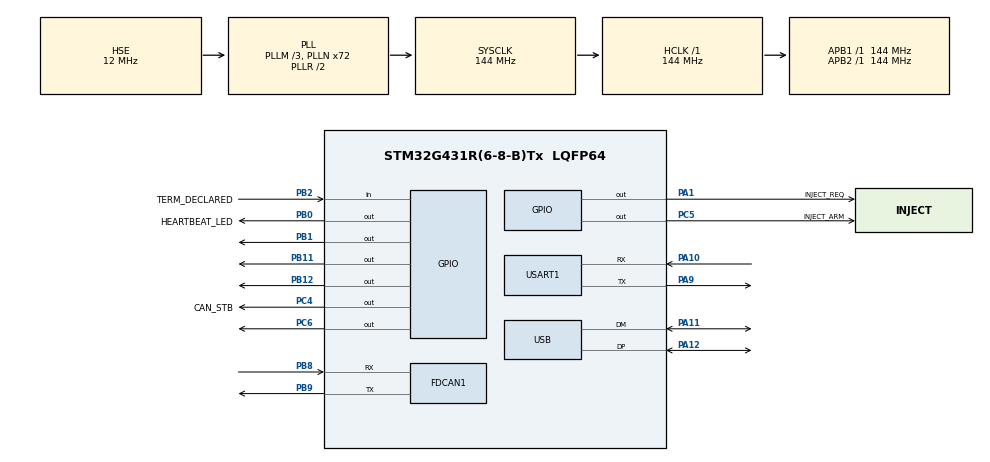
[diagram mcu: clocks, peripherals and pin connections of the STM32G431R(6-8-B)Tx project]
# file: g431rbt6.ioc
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FDCAN1.CalculateBaudRateNominal=8000000
FDCAN1.CalculateTimeBitNominal=125
FDCAN1.CalculateTimeQuantumNominal=41.666666666666664
FDCAN1.DataPrescaler=6
FDCAN1.DataSyncJumpWidth=2
FDCAN1.DataTimeSeg1=13
FDCAN1.DataTimeSeg2=2
FDCAN1.ExtFiltersNbr=1
FDCAN1.FrameFormat=FDCAN_FRAME_FD_NO_BRS
FDCAN1.NominalPrescaler=2
FDCAN1.NominalSyncJumpWidth=1
FDCAN1.ProtocolException=ENABLE
FDCAN1.StdFiltersNbr=1
Mcu.Family=STM32G4
Mcu.Name=STM32G431R(6-8-B)Tx
Mcu.Package=LQFP64
NVIC.FDCAN1_IT0_IRQn=true\:5\:0\:true\:false\:true\:true\:true\:true
NVIC.PriorityGroup=NVIC_PRIORITYGROUP_4
NVIC.TIM6_DAC_IRQn=true\:4\:0\:true\:false\:true\:false\:true\:true
NVIC.TimeBase=TIM6_DAC_IRQn
NVIC.TimeBaseIP=TIM6
NVIC.USB_LP_IRQn=true\:6\:0\:true\:false\:true\:true\:true\:true
PA1.GPIO_Label=INJECT_REQ
PA1.Signal=GPIO_Output
PA10.Mode=Asynchronous
PA10.Signal=USART1_RX
PA11.Mode=Device
PA11.Signal=USB_DM
PA12.Mode=Device
PA12.Signal=USB_DP
PA13.Mode=Serial_Wire
PA13.Signal=SYS_JTMS-SWDIO
PA14.Mode=Serial_Wire
PA14.Signal=SYS_JTCK-SWCLK
PA9.Mode=Asynchronous
PA9.Signal=USART1_TX
PB0.GPIO_Label=HEARTBEAT_LED
PB0.PinState=GPIO_PIN_SET
PB0.Signal=GPIO_Output
PB1.PinState=GPIO_PIN_SET
PB1.Signal=GPIO_Output
PB11.PinState=GPIO_PIN_SET
PB11.Signal=GPIO_Output
PB12.PinState=GPIO_PIN_SET
PB12.Signal=GPIO_Output
PB2.GPIO_Label=TERM_DECLARED
PB2.Signal=GPIO_Input
PB8-BOOT0.Mode=FDCAN_Activate
PB8-BOOT0.Signal=FDCAN1_RX
PB9.Mode=FDCAN_Activate
PB9.Signal=FDCAN1_TX
PC4.GPIO_Label=CAN_STB
PC4.PinState=GPIO_PIN_SET
PC4.Signal=GPIO_Output
PC5.GPIO_Label=INJECT_ARM
PC5.Signal=GPIO_Output
PC6.Signal=GPIO_Output
PF0-OSC_IN.Mode=HSE-External-Oscillator
PF0-OSC_IN.Signal=RCC_OSC_IN
PF1-OSC_OUT.Mode=HSE-External-Oscillator
PF1-OSC_OUT.Signal=RCC_OSC_OUT
ProjectManager.HeapSize=0x200
ProjectManager.StackSize=0x400
ProjectManager.TargetToolchain=CMake
RCC.ADC12Freq_Value=144000000
RCC.AHBFreq_Value=144000000
RCC.APB1Freq_Value=144000000
RCC.APB1TimFreq_Value=144000000
RCC.APB2Freq_Value=144000000
RCC.APB2TimFreq_Value=144000000
RCC.CortexFreq_Value=144000000
RCC.EXTERNAL_CLOCK_VALUE=12288000
RCC.EnbaleCSS=true
RCC.FDCANCLockSelection=RCC_FDCANCLKSOURCE_PLL
RCC.HCLKFreq_Value=144000000
RCC.HSE_VALUE=12000000
RCC.HSI48_VALUE=48000000
RCC.HSI_VALUE=16000000
RCC.LSE_VALUE=32768
RCC.PLLM=RCC_PLLM_DIV3
RCC.PLLN=72
RCC.PLLQ=RCC_PLLQ_DIV6
RCC.PLLSourceVirtual=RCC_PLLSOURCE_HSE
RCC.SYSCLKFreq_VALUE=144000000
RCC.SYSCLKSource=RCC_SYSCLKSOURCE_PLLCLK
RCC.USBFreq_Value=48000000
RCC.VCOOutputFreq_Value=288000000
USART1.VirtualMode-Asynchronous=VM_ASYNC
VP_SYS_VS_DBSignals.Mode=DisableDeadBatterySignals
VP_SYS_VS_tim6.Mode=TIM6
board=custom

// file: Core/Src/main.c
/* USER CODE BEGIN Header */
/**
  ******************************************************************************
  * @file           : main.c
  * @brief          : Main program body
  ******************************************************************************
  * @attention
  *
  * Copyright (c) 2026 STMicroelectronics.
  * All rights reserved.
  *
  * This software is licensed under terms that can be found in the LICENSE file
  * in the root directory of this software component.
  * If no LICENSE file comes with this software, it is provided AS-IS.
  *
  ******************************************************************************
  */
/* USER CODE END Header */
#include "main.h"

/* USER CODE BEGIN Includes */
#include "xcan_board.h"
/* USER CODE END Includes */

FDCAN_HandleTypeDef hfdcan1;

UART_HandleTypeDef huart1;

PCD_HandleTypeDef hpcd_USB_FS;

void SystemClock_Config(void);
static void MX_GPIO_Init(void);
static void MX_USART1_UART_Init(void);
static void MX_USB_PCD_Init(void);
static void MX_FDCAN1_Init(void);

int main(void)
{

  /* USER CODE BEGIN 1 */
  xcan_board_safe();
  /* USER CODE END 1 */

  /* MCU Configuration--------------------------------------------------------*/

  /* Reset of all peripherals, Initializes the Flash interface and the Systick. */
  HAL_Init();

  /* Configure the system clock */
  SystemClock_Config();

  /* Initialize all configured peripherals */
  MX_GPIO_Init();
  MX_USART1_UART_Init();
  MX_USB_PCD_Init();
  MX_FDCAN1_Init();
  /* USER CODE BEGIN 2 */
  xcan_board_init();
  xcan_start();
  /* USER CODE END 2 */

  /* Infinite loop */
  while (1)
  {

  }
}

void SystemClock_Config(void)
{
  RCC_OscInitTypeDef RCC_OscInitStruct = {0};
  RCC_ClkInitTypeDef RCC_ClkInitStruct = {0};

  /** Configure the main internal regulator output voltage
  */
  HAL_PWREx_ControlVoltageScaling(PWR_REGULATOR_VOLTAGE_SCALE1);

  /** Initializes the RCC Oscillators according to the specified parameters
  * in the RCC_OscInitTypeDef structure.
  */
  RCC_OscInitStruct.OscillatorType = RCC_OSCILLATORTYPE_HSE;
  RCC_OscInitStruct.HSEState = RCC_HSE_ON;
  RCC_OscInitStruct.PLL.PLLState = RCC_PLL_ON;
  RCC_OscInitStruct.PLL.PLLSource = RCC_PLLSOURCE_HSE;
  RCC_OscInitStruct.PLL.PLLM = RCC_PLLM_DIV3;
  RCC_OscInitStruct.PLL.PLLN = 72;
  RCC_OscInitStruct.PLL.PLLP = RCC_PLLP_DIV2;
  RCC_OscInitStruct.PLL.PLLQ = RCC_PLLQ_DIV6;
  RCC_OscInitStruct.PLL.PLLR = RCC_PLLR_DIV2;
  if (HAL_RCC_OscConfig(&RCC_OscInitStruct) != HAL_OK)
  {
    Error_Handler();
  }

  /** Initializes the CPU, AHB and APB buses clocks
  */
  RCC_ClkInitStruct.ClockType = RCC_CLOCKTYPE_HCLK|RCC_CLOCKTYPE_SYSCLK
                              |RCC_CLOCKTYPE_PCLK1|RCC_CLOCKTYPE_PCLK2;
  RCC_ClkInitStruct.SYSCLKSource = RCC_SYSCLKSOURCE_PLLCLK;
  RCC_ClkInitStruct.AHBCLKDivider = RCC_SYSCLK_DIV1;
  RCC_ClkInitStruct.APB1CLKDivider = RCC_HCLK_DIV1;
  RCC_ClkInitStruct.APB2CLKDivider = RCC_HCLK_DIV1;

  if (HAL_RCC_ClockConfig(&RCC_ClkInitStruct, FLASH_LATENCY_4) != HAL_OK)
  {
    Error_Handler();
  }

  /** Enables the Clock Security System
  */
  HAL_RCC_EnableCSS();
}

static void MX_FDCAN1_Init(void)
{

  hfdcan1.Instance = FDCAN1;
  hfdcan1.Init.ClockDivider = FDCAN_CLOCK_DIV1;
  hfdcan1.Init.FrameFormat = FDCAN_FRAME_FD_NO_BRS;
  hfdcan1.Init.Mode = FDCAN_MODE_NORMAL;
  hfdcan1.Init.AutoRetransmission = DISABLE;
  hfdcan1.Init.TransmitPause = DISABLE;
  hfdcan1.Init.ProtocolException = ENABLE;
  hfdcan1.Init.NominalPrescaler = 2;
  hfdcan1.Init.NominalSyncJumpWidth = 1;
  hfdcan1.Init.NominalTimeSeg1 = 1;
  hfdcan1.Init.NominalTimeSeg2 = 1;
  hfdcan1.Init.DataPrescaler = 6;
  hfdcan1.Init.DataSyncJumpWidth = 2;
  hfdcan1.Init.DataTimeSeg1 = 13;
  hfdcan1.Init.DataTimeSeg2 = 2;
  hfdcan1.Init.StdFiltersNbr = 1;
  hfdcan1.Init.ExtFiltersNbr = 1;
  hfdcan1.Init.TxFifoQueueMode = FDCAN_TX_FIFO_OPERATION;
  if (HAL_FDCAN_Init(&hfdcan1) != HAL_OK)
  {
    Error_Handler();
  }

}

static void MX_USART1_UART_Init(void)
{

  huart1.Instance = USART1;
  huart1.Init.BaudRate = 115200;
  huart1.Init.WordLength = UART_WORDLENGTH_8B;
  huart1.Init.StopBits = UART_STOPBITS_1;
  huart1.Init.Parity = UART_PARITY_NONE;
  huart1.Init.Mode = UART_MODE_TX_RX;
  huart1.Init.HwFlowCtl = UART_HWCONTROL_NONE;
  huart1.Init.OverSampling = UART_OVERSAMPLING_16;
  huart1.Init.OneBitSampling = UART_ONE_BIT_SAMPLE_DISABLE;
  huart1.Init.ClockPrescaler = UART_PRESCALER_DIV1;
  huart1.AdvancedInit.AdvFeatureInit = UART_ADVFEATURE_NO_INIT;
  if (HAL_UART_Init(&huart1) != HAL_OK)
  {
    Error_Handler();
  }
  if (HAL_UARTEx_SetTxFifoThreshold(&huart1, UART_TXFIFO_THRESHOLD_1_8) != HAL_OK)
  {
    Error_Handler();
  }
  if (HAL_UARTEx_SetRxFifoThreshold(&huart1, UART_RXFIFO_THRESHOLD_1_8) != HAL_OK)
  {
    Error_Handler();
  }
  if (HAL_UARTEx_DisableFifoMode(&huart1) != HAL_OK)
  {
    Error_Handler();
  }

}

static void MX_USB_PCD_Init(void)
{

  /* USER CODE BEGIN USB_Init 0 */
  /* CherryUSB owns the controller; CubeMX retains clock/pin configuration. */
  hpcd_USB_FS.Instance = USB;
  HAL_PCD_MspInit(&hpcd_USB_FS);
  return;
  /* USER CODE END USB_Init 0 */

  hpcd_USB_FS.Instance = USB;
  hpcd_USB_FS.Init.dev_endpoints = 8;
  hpcd_USB_FS.Init.speed = PCD_SPEED_FULL;
  hpcd_USB_FS.Init.phy_itface = PCD_PHY_EMBEDDED;
  hpcd_USB_FS.Init.Sof_enable = DISABLE;
  hpcd_USB_FS.Init.low_power_enable = DISABLE;
  hpcd_USB_FS.Init.lpm_enable = DISABLE;
  hpcd_USB_FS.Init.battery_charging_enable = DISABLE;
  if (HAL_PCD_Init(&hpcd_USB_FS) != HAL_OK)
  {
    Error_Handler();
  }

}

static void MX_GPIO_Init(void)
{
  GPIO_InitTypeDef GPIO_InitStruct = {0};

  /* GPIO Ports Clock Enable */
  __HAL_RCC_GPIOC_CLK_ENABLE();
  __HAL_RCC_GPIOF_CLK_ENABLE();
  __HAL_RCC_GPIOG_CLK_ENABLE();
  __HAL_RCC_GPIOA_CLK_ENABLE();
  __HAL_RCC_GPIOB_CLK_ENABLE();
  __HAL_RCC_GPIOD_CLK_ENABLE();

  /*Configure GPIO pin Output Level */
  HAL_GPIO_WritePin(INJECT_REQ_GPIO_Port, INJECT_REQ_Pin, GPIO_PIN_RESET);

  /*Configure GPIO pin Output Level */
  HAL_GPIO_WritePin(CAN_STB_GPIO_Port, CAN_STB_Pin, GPIO_PIN_SET);

  /*Configure GPIO pin Output Level */
  HAL_GPIO_WritePin(GPIOC, INJECT_ARM_Pin|GPIO_PIN_6, GPIO_PIN_RESET);

  /*Configure GPIO pin Output Level */
  HAL_GPIO_WritePin(GPIOB, HEARTBEAT_LED_Pin|GPIO_PIN_1|GPIO_PIN_11|GPIO_PIN_12, GPIO_PIN_SET);

  /*Configure GPIO pins : PC13 PC14 PC15 PC0
                           PC1 PC2 PC3 PC7
                           PC8 PC9 PC10 PC11
                           PC12 */
  GPIO_InitStruct.Pin = GPIO_PIN_13|GPIO_PIN_14|GPIO_PIN_15|GPIO_PIN_0
                          |GPIO_PIN_1|GPIO_PIN_2|GPIO_PIN_3|GPIO_PIN_7
                          |GPIO_PIN_8|GPIO_PIN_9|GPIO_PIN_10|GPIO_PIN_11
                          |GPIO_PIN_12;
  GPIO_InitStruct.Mode = GPIO_MODE_ANALOG;
  GPIO_InitStruct.Pull = GPIO_NOPULL;
  HAL_GPIO_Init(GPIOC, &GPIO_InitStruct);

  /*Configure GPIO pin : PG10 */
  GPIO_InitStruct.Pin = GPIO_PIN_10;
  GPIO_InitStruct.Mode = GPIO_MODE_ANALOG;
  GPIO_InitStruct.Pull = GPIO_NOPULL;
  HAL_GPIO_Init(GPIOG, &GPIO_InitStruct);

  /*Configure GPIO pins : PA0 PA2 PA3 PA4
                           PA5 PA6 PA7 PA8
                           PA15 */
  GPIO_InitStruct.Pin = GPIO_PIN_0|GPIO_PIN_2|GPIO_PIN_3|GPIO_PIN_4
                          |GPIO_PIN_5|GPIO_PIN_6|GPIO_PIN_7|GPIO_PIN_8
                          |GPIO_PIN_15;
  GPIO_InitStruct.Mode = GPIO_MODE_ANALOG;
  GPIO_InitStruct.Pull = GPIO_NOPULL;
  HAL_GPIO_Init(GPIOA, &GPIO_InitStruct);

  /*Configure GPIO pin : INJECT_REQ_Pin */
  GPIO_InitStruct.Pin = INJECT_REQ_Pin;
  GPIO_InitStruct.Mode = GPIO_MODE_OUTPUT_PP;
  GPIO_InitStruct.Pull = GPIO_NOPULL;
  GPIO_InitStruct.Speed = GPIO_SPEED_FREQ_LOW;
  HAL_GPIO_Init(INJECT_REQ_GPIO_Port, &GPIO_InitStruct);

  /*Configure GPIO pins : CAN_STB_Pin INJECT_ARM_Pin PC6 */
  GPIO_InitStruct.Pin = CAN_STB_Pin|INJECT_ARM_Pin|GPIO_PIN_6;
  GPIO_InitStruct.Mode = GPIO_MODE_OUTPUT_PP;
  GPIO_InitStruct.Pull = GPIO_NOPULL;
  GPIO_InitStruct.Speed = GPIO_SPEED_FREQ_LOW;
  HAL_GPIO_Init(GPIOC, &GPIO_InitStruct);

  /*Configure GPIO pins : HEARTBEAT_LED_Pin PB1 PB11 PB12 */
  GPIO_InitStruct.Pin = HEARTBEAT_LED_Pin|GPIO_PIN_1|GPIO_PIN_11|GPIO_PIN_12;
  GPIO_InitStruct.Mode = GPIO_MODE_OUTPUT_PP;
  GPIO_InitStruct.Pull = GPIO_NOPULL;
  GPIO_InitStruct.Speed = GPIO_SPEED_FREQ_LOW;
  HAL_GPIO_Init(GPIOB, &GPIO_InitStruct);

  /*Configure GPIO pin : TERM_DECLARED_Pin */
  GPIO_InitStruct.Pin = TERM_DECLARED_Pin;
  GPIO_InitStruct.Mode = GPIO_MODE_INPUT;
  GPIO_InitStruct.Pull = GPIO_NOPULL;
  HAL_GPIO_Init(TERM_DECLARED_GPIO_Port, &GPIO_InitStruct);

  /*Configure GPIO pins : PB10 PB13 PB14 PB15
                           PB3 PB4 PB5 PB6
                           PB7 */
  GPIO_InitStruct.Pin = GPIO_PIN_10|GPIO_PIN_13|GPIO_PIN_14|GPIO_PIN_15
                          |GPIO_PIN_3|GPIO_PIN_4|GPIO_PIN_5|GPIO_PIN_6
                          |GPIO_PIN_7;
  GPIO_InitStruct.Mode = GPIO_MODE_ANALOG;
  GPIO_InitStruct.Pull = GPIO_NOPULL;
  HAL_GPIO_Init(GPIOB, &GPIO_InitStruct);

  /*Configure GPIO pin : PD2 */
  GPIO_InitStruct.Pin = GPIO_PIN_2;
  GPIO_InitStruct.Mode = GPIO_MODE_ANALOG;
  GPIO_InitStruct.Pull = GPIO_NOPULL;
  HAL_GPIO_Init(GPIOD, &GPIO_InitStruct);

}

void HAL_TIM_PeriodElapsedCallback(TIM_HandleTypeDef *htim)
{
  if (htim->Instance == TIM6)
  {
    HAL_IncTick();
  }
}

void Error_Handler(void)
{
  /* USER CODE BEGIN Error_Handler_Debug */
  xcan_fatal();
  /* USER CODE END Error_Handler_Debug */
}
